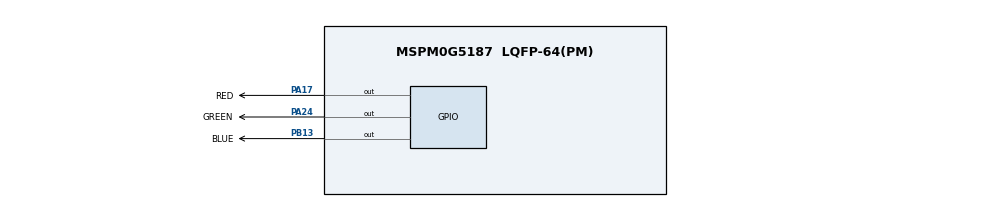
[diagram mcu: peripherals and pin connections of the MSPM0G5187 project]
//@cliArgs --device "MSPM0G518X" --package "LQFP-64(PM)" --part "Default"
//@v2CliArgs --device "MSPM0G5187" --package "LQFP-64(PM)"
// @cliArgs --board /ti/boards/LP_MSPM0G5187 --rtos nortos

/**
 * Import the modules used in this configuration.
 */
const ADC12         = scripting.addModule("/ti/driverlib/ADC12", {}, false);
const ADC121        = ADC12.addInstance();
const GPIO          = scripting.addModule("/ti/driverlib/GPIO", {}, false);
const GPIO1         = GPIO.addInstance();
const SYSCTL        = scripting.addModule("/ti/driverlib/SYSCTL");
const VREF          = scripting.addModule("/ti/driverlib/VREF");
const ProjectConfig = scripting.addModule("/ti/project_config/ProjectConfig");

/**
 * Write custom configuration values to the imported modules.
 */
const divider9       = system.clockTree["UDIV"];
divider9.divideValue = 2;

const multiplier2         = system.clockTree["PLL_QDIV"];
multiplier2.multiplyValue = 5;

const mux7       = system.clockTree["HSCLKMUX"];
mux7.inputSelect = "HSCLKMUX_SYSPLL0";

ADC121.$name               = "ADC12_0";
ADC121.repeatMode          = true;
ADC121.adcMem0vrefm        = "VREFM";
ADC121.resolution          = "DL_ADC12_SAMP_CONV_RES_8_BIT";
ADC121.sampleTime0         = "32 ms";
ADC121.sampClkDiv          = "DL_ADC12_CLOCK_DIVIDE_16";
ADC121.enabledInterrupts   = ["DL_ADC12_INTERRUPT_MEM0_RESULT_LOADED"];
ADC121.adcMem0chansel      = "DL_ADC12_INPUT_CHAN_7";
ADC121.peripheral.$assign  = "ADC0";
ADC121.peripheral.adcPin7.$assign = "PA22";

GPIO1.$name                              = "LED";
GPIO1.associatedPins.create(3);
GPIO1.associatedPins[0].$name            = "RED";
GPIO1.associatedPins[0].pin.$assign      = "PA17";
GPIO1.associatedPins[1].$name            = "BLUE";
GPIO1.associatedPins[1].pin.$assign      = "PB13";
GPIO1.associatedPins[2].$name            = "GREEN";
GPIO1.associatedPins[2].internalResistor = "PULL_UP";
GPIO1.associatedPins[2].pin.$assign      = "PA24";

SYSCTL.forceDefaultClkConfig = true;
SYSCTL.clockTreeEn           = true;

VREF.basicExtVolt                  = 3.3;
VREF.basicMode                     = "DL_VREF_ENABLE_ENABLE_DL_VREF_ENABLE_DISABLE";
VREF.basicVrefPins                 = "VREF+-";
VREF.peripheral.$assign            = "VREF";

ProjectConfig.genLibCMSIS        = true;
ProjectConfig.migrationCondition = true;
ProjectConfig.genLibNPU          = true;
